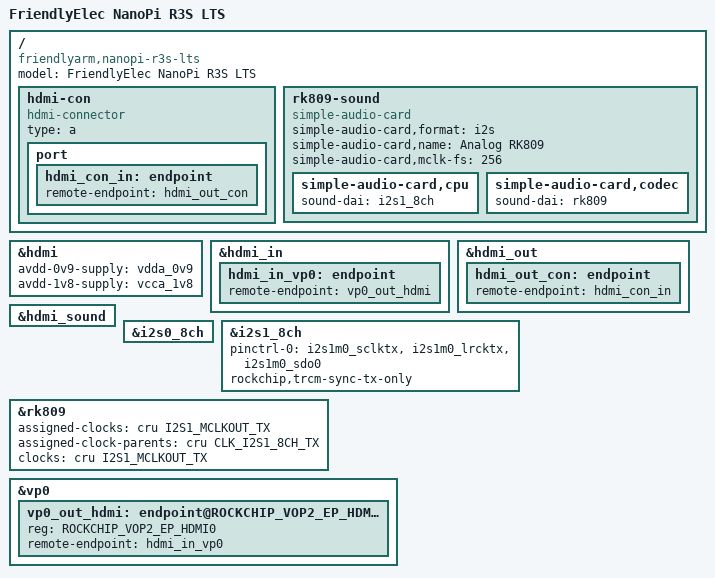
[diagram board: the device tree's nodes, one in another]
/dts-v1/;

#include <dt-bindings/soc/rockchip,vop2.h>
#include "rk3566-nanopi-r3s.dts"

/ {
	model = "FriendlyElec NanoPi R3S LTS";
	compatible = "friendlyarm,nanopi-r3s-lts", "friendlyarm,nanopi-r3s", "rockchip,rk3566";

	hdmi-con {
		compatible = "hdmi-connector";
		type = "a";

		port {
			hdmi_con_in: endpoint {
				remote-endpoint = <&hdmi_out_con>;
			};
		};
	};

	rk809-sound {
		compatible = "simple-audio-card";
		simple-audio-card,format = "i2s";
		simple-audio-card,name = "Analog RK809";
		simple-audio-card,mclk-fs = <256>;

		simple-audio-card,cpu {
			sound-dai = <&i2s1_8ch>;
		};

		simple-audio-card,codec {
			sound-dai = <&rk809>;
		};
	};
};

&hdmi {
	avdd-0v9-supply = <&vdda_0v9>;
	avdd-1v8-supply = <&vcca_1v8>;
	status = "okay";
};

&hdmi_in {
	hdmi_in_vp0: endpoint {
		remote-endpoint = <&vp0_out_hdmi>;
	};
};

&hdmi_out {
	hdmi_out_con: endpoint {
		remote-endpoint = <&hdmi_con_in>;
	};
};

&hdmi_sound {
	status = "okay";
};

&i2s0_8ch {
	status = "okay";
};

&i2s1_8ch {
	pinctrl-names = "default";
	pinctrl-0 = <&i2s1m0_sclktx &i2s1m0_lrcktx &i2s1m0_sdo0>;
	rockchip,trcm-sync-tx-only;
	status = "okay";
};

&rk809 {
	assigned-clocks = <&cru I2S1_MCLKOUT_TX>;
	assigned-clock-parents = <&cru CLK_I2S1_8CH_TX>;
	clock-names = "mclk";
	clocks = <&cru I2S1_MCLKOUT_TX>;
	#sound-dai-cells = <0>;
};

&vp0 {
	vp0_out_hdmi: endpoint@ROCKCHIP_VOP2_EP_HDMI0 {
		reg = <ROCKCHIP_VOP2_EP_HDMI0>;
		remote-endpoint = <&hdmi_in_vp0>;
	};
};
